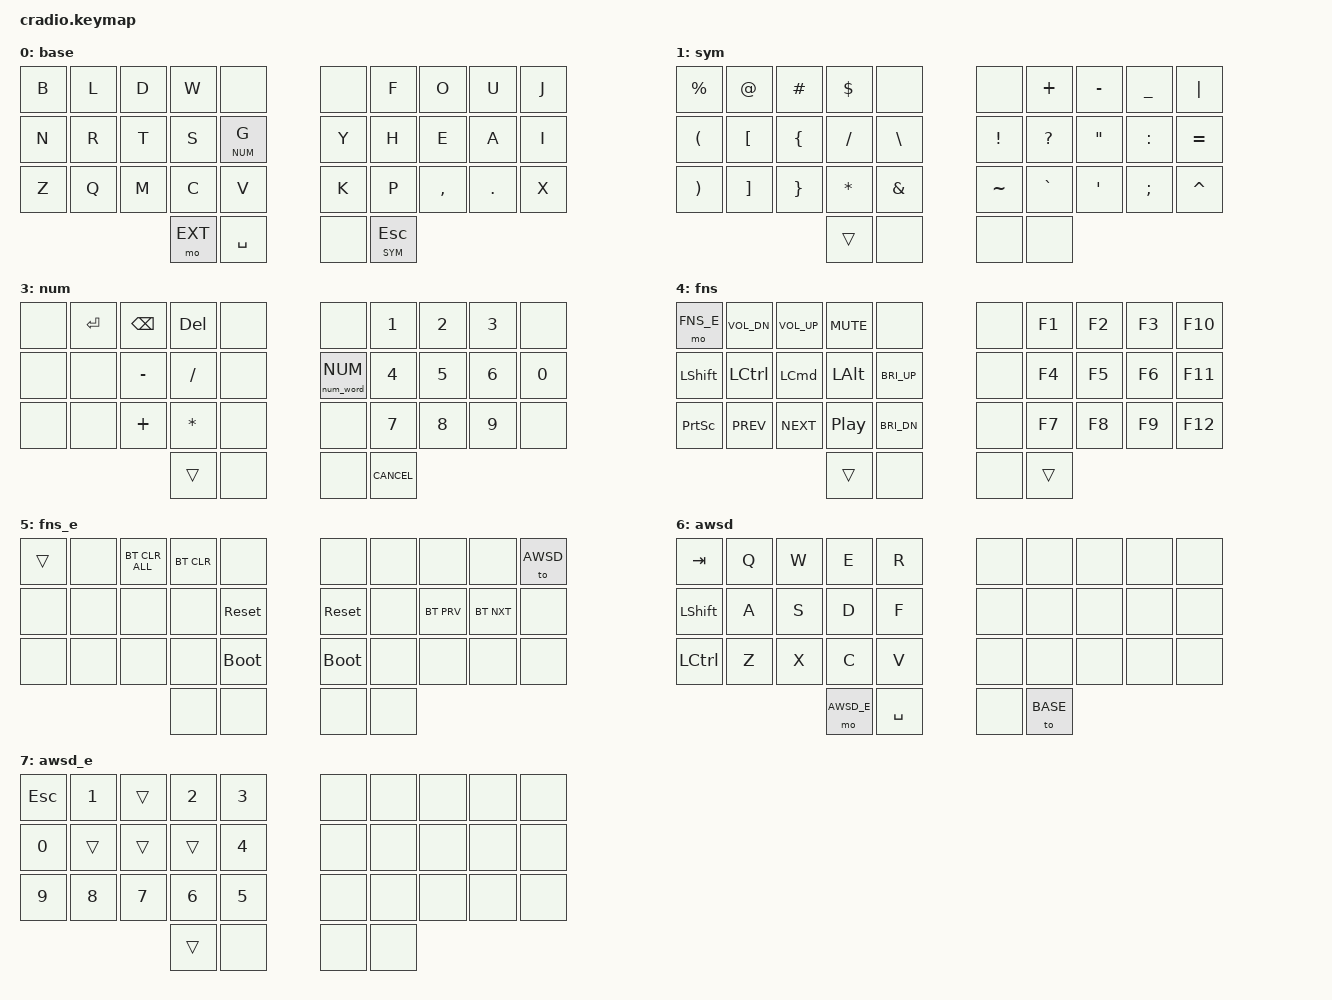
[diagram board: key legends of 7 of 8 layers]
#include <behaviors.dtsi>
#include <behaviors/num_word.dtsi>
#include <dt-bindings/zmk/keys.h>
#include <dt-bindings/zmk/bt.h>

#define BASE 0
#define SYM 1
#define EXT 2
#define NUM 3
#define FNS 4
#define FNS_E 5
#define AWSD 6
#define AWSD_E 7

#define PRIOR_IDLE 125

&sk {
    release-after-ms = <2000>;
};

&num_word {
    ignore-modifiers;
};

/ {
    behaviors {
        blt: blt {
            compatible = "zmk,behavior-hold-tap";
            #binding-cells = <2>;
            flavor = "balanced";
            tapping-term-ms = <200>;
            require-prior-idle-ms = <PRIOR_IDLE>;
            bindings = <&mo>, <&kp>;
        };

        alt_tab: alt_tab {
            compatible = "zmk,behavior-tri-state";
            #binding-cells = <0>;
            bindings = <&kt LALT>, <&kp TAB>, <&kt LALT>;
            ignored-key-positions = <22>;
        };
    };

    combos {
        compatible = "zmk,combos";

        combo_fns {
            timeout-ms = <50>;
            require-prior-idle-ms = <PRIOR_IDLE>;
            key-positions = <30 33>;
            bindings = <&sl FNS>;
        };
    };

    keymap {
        compatible = "zmk,keymap";

        base {
            bindings = <
                &kp B  &kp L  &kp D  &kp W  &none         &none  &kp F  &kp O      &kp U    &kp J
                &kp N  &kp R  &kp T  &kp S  &blt NUM G    &kp Y  &kp H  &kp E      &kp A    &kp I
                &kp Z  &kp Q  &kp M  &kp C  &kp V         &kp K  &kp P  &kp COMMA  &kp DOT  &kp X
                &mo EXT  &kp SPACE                        &none  &blt SYM ESC
            >;
        };

        sym {
            bindings = <
                &kp PRCNT  &kp AT    &kp HASH  &kp DLLR  &none       &none      &kp PLUS   &kp MINUS  &kp UNDER  &kp PIPE
                &kp LPAR   &kp LBKT  &kp LBRC  &kp FSLH  &kp BSLH    &kp EXCL   &kp QMARK  &kp DQT    &kp COLON  &kp EQUAL
                &kp RPAR   &kp RBKT  &kp RBRC  &kp STAR  &kp AMPS    &kp TILDE  &kp GRAVE  &kp SQT    &kp SEMI   &kp CARET
                &trans  &none                                        &none  &none
            >;
        };

        ext {
            bindings = <
                &alt_tab   &kp RET    &kp BSPC   &kp DEL    &none        &none       &kp PG_DN    &kp HOME  &kp END  &kp PG_UP
                &sk LSHFT  &sk LCTRL  &sk LCMD   &sk LALT   &kp TAB      &caps_word  &kp LEFT     &kp DOWN  &kp UP   &kp RIGHT
                &kp LC(Z)  &kp LC(A)  &kp LC(X)  &kp LC(C)  &kp LC(V)    &none       &key_repeat  &none     &none    m&none
                &trans  &none                                            &none  &trans
            >;
        };

        num {
            bindings = <
                &none  &kp RET  &kp BSPC   &kp DEL   &none    &none          &kp N1  &kp N2  &kp N3  &none
                &none  &none    &kp MINUS  &kp FSLH  &none    &num_word NUM  &kp N4  &kp N5  &kp N6  &kp N0
                &none  &none    &kp PLUS   &kp STAR  &none    &none          &kp N7  &kp N8  &kp N9  &none
                &trans  &none                                 &none  &kp K_CANCEL
            >;
        };

        fns {
            bindings = <
                &mo FNS_E  &kp C_VOL_DN  &kp C_VOL_UP  &kp C_MUTE  &none           &none  &kp F1  &kp F2  &kp F3  &kp F10
                &kp LSHFT  &kp LCTRL     &kp LCMD      &kp LALT    &kp C_BRI_UP    &none  &kp F4  &kp F5  &kp F6  &kp F11
                &kp PSCRN  &kp C_PREV    &kp C_NEXT    &kp C_PP    &kp C_BRI_DN    &none  &kp F7  &kp F8  &kp F9  &kp F12
                &trans  &none                                                      &none  &trans
            >;
        };

        fns_e {
            bindings = <
                &trans  &none  &bt BT_CLR_ALL  &bt BT_CLR  &none          &none        &none  &none       &none       &to AWSD
                &none   &none  &none           &none       &sys_reset     &sys_reset   &none  &bt BT_PRV  &bt BT_NXT  &none
                &none   &none  &none           &none       &bootloader    &bootloader  &none  &none       &none       &none
                &none  &none                                              &none  &none
            >;
        };

        awsd {
            bindings = <
                &kp TAB    &kp Q  &kp W  &kp E  &kp R    &none  &none  &none  &none  &none
                &kp LSHFT  &kp A  &kp S  &kp D  &kp F    &none  &none  &none  &none  &none
                &kp LCTRL  &kp Z  &kp X  &kp C  &kp V    &none  &none  &none  &none  &none
                &mo AWSD_E  &kp SPACE                    &none  &to BASE
            >;
        };

        awsd_e {
            bindings = <
                &kp ESC  &kp N1  &trans  &kp N2  &kp N3    &none  &none  &none  &none  &none
                &kp N0   &trans  &trans  &trans  &kp N4    &none  &none  &none  &none  &none
                &kp N9   &kp N8  &kp N7  &kp N6  &kp N5    &none  &none  &none  &none  &none
                &trans  &none                              &none  &none
            >;
        };
    };
};
